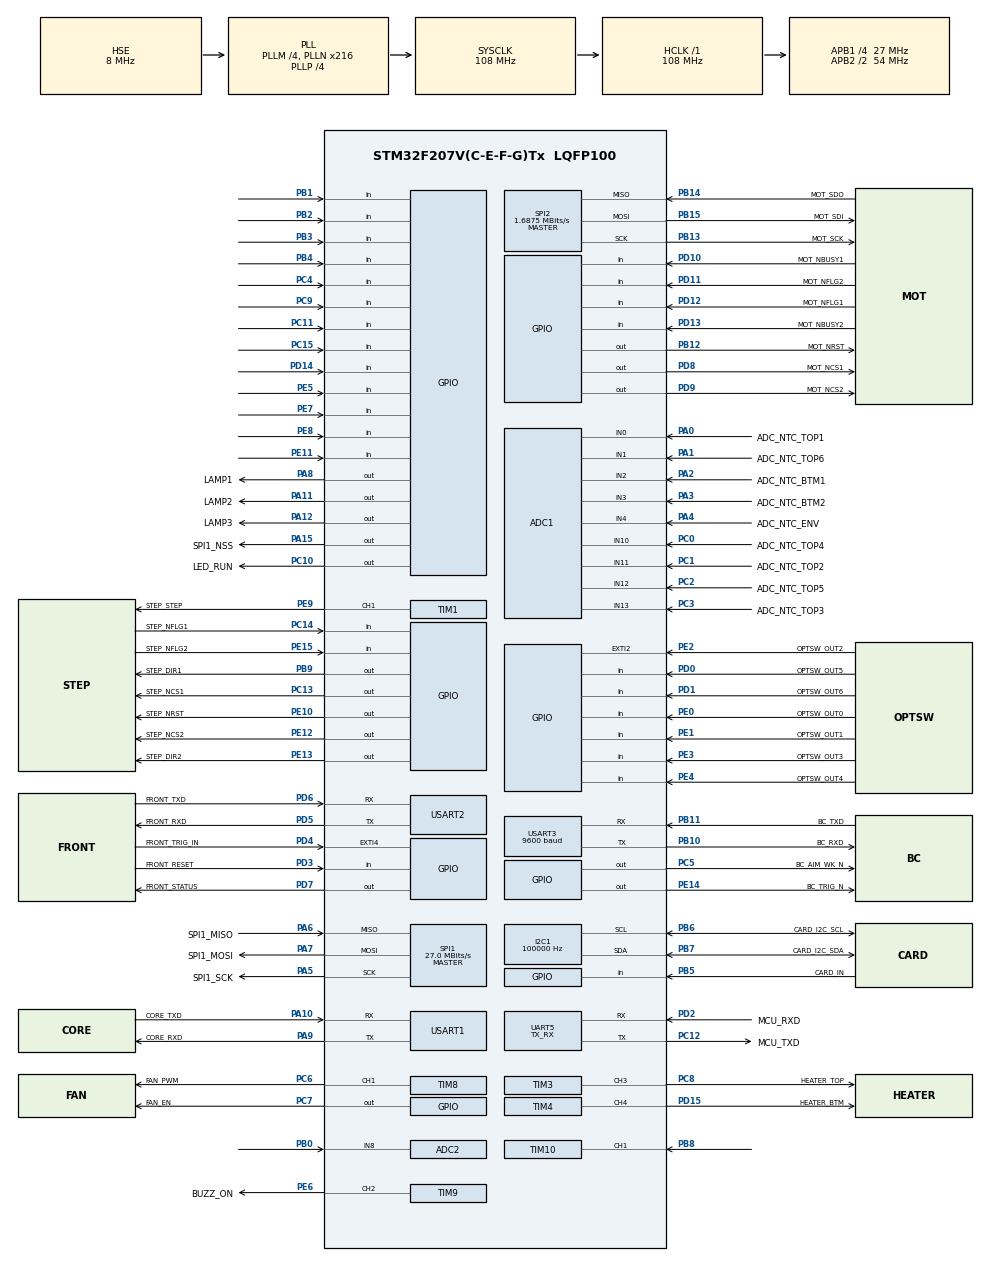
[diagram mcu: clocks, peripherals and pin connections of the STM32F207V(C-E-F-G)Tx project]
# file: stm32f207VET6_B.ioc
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ADC1.Channel-0\#ChannelRegularConversion=ADC_CHANNEL_0
ADC1.Channel-1\#ChannelRegularConversion=ADC_CHANNEL_11
ADC1.Channel-2\#ChannelRegularConversion=ADC_CHANNEL_13
ADC1.Channel-3\#ChannelRegularConversion=ADC_CHANNEL_10
ADC1.Channel-4\#ChannelRegularConversion=ADC_CHANNEL_12
ADC1.Channel-5\#ChannelRegularConversion=ADC_CHANNEL_1
ADC1.Channel-6\#ChannelRegularConversion=ADC_CHANNEL_2
ADC1.Channel-7\#ChannelRegularConversion=ADC_CHANNEL_3
ADC1.Channel-8\#ChannelRegularConversion=ADC_CHANNEL_4
ADC1.ContinuousConvMode=DISABLE
ADC1.DMAContinuousRequests=ENABLE
ADC1.EOCSelection=ADC_EOC_SEQ_CONV
ADC1.ExternalTrigConv=ADC_EXTERNALTRIGCONV_T2_TRGO
ADC1.NbrOfConversion=9
ADC1.NbrOfConversionFlag=1
ADC1.Rank-0\#ChannelRegularConversion=1
ADC1.Rank-1\#ChannelRegularConversion=2
ADC1.Rank-2\#ChannelRegularConversion=3
ADC1.Rank-3\#ChannelRegularConversion=4
ADC1.Rank-4\#ChannelRegularConversion=5
ADC1.Rank-5\#ChannelRegularConversion=6
ADC1.Rank-6\#ChannelRegularConversion=7
ADC1.Rank-7\#ChannelRegularConversion=8
ADC1.Rank-8\#ChannelRegularConversion=9
ADC1.SamplingTime-0\#ChannelRegularConversion=ADC_SAMPLETIME_56CYCLES
ADC1.SamplingTime-1\#ChannelRegularConversion=ADC_SAMPLETIME_56CYCLES
ADC1.SamplingTime-2\#ChannelRegularConversion=ADC_SAMPLETIME_56CYCLES
ADC1.SamplingTime-3\#ChannelRegularConversion=ADC_SAMPLETIME_56CYCLES
ADC1.SamplingTime-4\#ChannelRegularConversion=ADC_SAMPLETIME_56CYCLES
ADC1.SamplingTime-5\#ChannelRegularConversion=ADC_SAMPLETIME_56CYCLES
ADC1.SamplingTime-6\#ChannelRegularConversion=ADC_SAMPLETIME_56CYCLES
ADC1.SamplingTime-7\#ChannelRegularConversion=ADC_SAMPLETIME_56CYCLES
ADC1.SamplingTime-8\#ChannelRegularConversion=ADC_SAMPLETIME_56CYCLES
ADC1.master=1
ADC2.Channel-0\#ChannelRegularConversion=ADC_CHANNEL_8
ADC2.NbrOfConversion=1
ADC2.NbrOfConversionFlag=1
ADC2.Rank-0\#ChannelRegularConversion=1
ADC2.SamplingTime-0\#ChannelRegularConversion=ADC_SAMPLETIME_56CYCLES
Dma.ADC1.6.Direction=DMA_PERIPH_TO_MEMORY
Dma.ADC1.6.FIFOMode=DMA_FIFOMODE_DISABLE
Dma.ADC1.6.Instance=DMA2_Stream0
Dma.ADC1.6.MemDataAlignment=DMA_MDATAALIGN_WORD
Dma.ADC1.6.MemInc=DMA_MINC_ENABLE
Dma.ADC1.6.Mode=DMA_CIRCULAR
Dma.ADC1.6.PeriphDataAlignment=DMA_PDATAALIGN_WORD
Dma.ADC1.6.PeriphInc=DMA_PINC_DISABLE
Dma.ADC1.6.Priority=DMA_PRIORITY_MEDIUM
Dma.Request0=UART5_RX
Dma.Request1=USART1_RX
Dma.Request2=USART1_TX
Dma.Request3=USART2_RX
Dma.Request4=USART2_TX
Dma.Request5=TIM1_UP
Dma.Request6=ADC1
Dma.Request7=UART5_TX
Dma.TIM1_UP.5.Direction=DMA_MEMORY_TO_PERIPH
Dma.TIM1_UP.5.FIFOMode=DMA_FIFOMODE_DISABLE
Dma.TIM1_UP.5.Instance=DMA2_Stream5
Dma.TIM1_UP.5.MemDataAlignment=DMA_MDATAALIGN_WORD
Dma.TIM1_UP.5.MemInc=DMA_MINC_ENABLE
Dma.TIM1_UP.5.Mode=DMA_NORMAL
Dma.TIM1_UP.5.PeriphDataAlignment=DMA_PDATAALIGN_WORD
Dma.TIM1_UP.5.PeriphInc=DMA_PINC_DISABLE
Dma.TIM1_UP.5.Priority=DMA_PRIORITY_HIGH
Dma.UART5_RX.0.Direction=DMA_PERIPH_TO_MEMORY
Dma.UART5_RX.0.FIFOMode=DMA_FIFOMODE_DISABLE
Dma.UART5_RX.0.Instance=DMA1_Stream0
Dma.UART5_RX.0.MemDataAlignment=DMA_MDATAALIGN_BYTE
Dma.UART5_RX.0.MemInc=DMA_MINC_ENABLE
Dma.UART5_RX.0.Mode=DMA_CIRCULAR
Dma.UART5_RX.0.PeriphDataAlignment=DMA_PDATAALIGN_BYTE
Dma.UART5_RX.0.PeriphInc=DMA_PINC_DISABLE
Dma.UART5_RX.0.Priority=DMA_PRIORITY_LOW
Dma.UART5_TX.7.Direction=DMA_MEMORY_TO_PERIPH
Dma.UART5_TX.7.FIFOMode=DMA_FIFOMODE_DISABLE
Dma.UART5_TX.7.Instance=DMA1_Stream7
Dma.UART5_TX.7.MemDataAlignment=DMA_MDATAALIGN_BYTE
Dma.UART5_TX.7.MemInc=DMA_MINC_ENABLE
Dma.UART5_TX.7.Mode=DMA_NORMAL
Dma.UART5_TX.7.PeriphDataAlignment=DMA_PDATAALIGN_BYTE
Dma.UART5_TX.7.PeriphInc=DMA_PINC_DISABLE
Dma.UART5_TX.7.Priority=DMA_PRIORITY_MEDIUM
Dma.USART1_RX.1.Direction=DMA_PERIPH_TO_MEMORY
Dma.USART1_RX.1.FIFOMode=DMA_FIFOMODE_DISABLE
Dma.USART1_RX.1.Instance=DMA2_Stream2
Dma.USART1_RX.1.MemDataAlignment=DMA_MDATAALIGN_BYTE
Dma.USART1_RX.1.MemInc=DMA_MINC_ENABLE
Dma.USART1_RX.1.Mode=DMA_CIRCULAR
Dma.USART1_RX.1.PeriphDataAlignment=DMA_PDATAALIGN_BYTE
Dma.USART1_RX.1.PeriphInc=DMA_PINC_DISABLE
Dma.USART1_RX.1.Priority=DMA_PRIORITY_LOW
Dma.USART1_TX.2.Direction=DMA_MEMORY_TO_PERIPH
Dma.USART1_TX.2.FIFOMode=DMA_FIFOMODE_DISABLE
Dma.USART1_TX.2.Instance=DMA2_Stream7
Dma.USART1_TX.2.MemDataAlignment=DMA_MDATAALIGN_BYTE
Dma.USART1_TX.2.MemInc=DMA_MINC_ENABLE
Dma.USART1_TX.2.Mode=DMA_NORMAL
Dma.USART1_TX.2.PeriphDataAlignment=DMA_PDATAALIGN_BYTE
Dma.USART1_TX.2.PeriphInc=DMA_PINC_DISABLE
Dma.USART1_TX.2.Priority=DMA_PRIORITY_MEDIUM
Dma.USART2_RX.3.Direction=DMA_PERIPH_TO_MEMORY
Dma.USART2_RX.3.FIFOMode=DMA_FIFOMODE_DISABLE
Dma.USART2_RX.3.Instance=DMA1_Stream5
Dma.USART2_RX.3.MemDataAlignment=DMA_MDATAALIGN_BYTE
Dma.USART2_RX.3.MemInc=DMA_MINC_ENABLE
Dma.USART2_RX.3.Mode=DMA_CIRCULAR
Dma.USART2_RX.3.PeriphDataAlignment=DMA_PDATAALIGN_BYTE
Dma.USART2_RX.3.PeriphInc=DMA_PINC_DISABLE
Dma.USART2_RX.3.Priority=DMA_PRIORITY_HIGH
Dma.USART2_TX.4.Direction=DMA_MEMORY_TO_PERIPH
Dma.USART2_TX.4.FIFOMode=DMA_FIFOMODE_DISABLE
Dma.USART2_TX.4.Instance=DMA1_Stream6
Dma.USART2_TX.4.MemDataAlignment=DMA_MDATAALIGN_BYTE
Dma.USART2_TX.4.MemInc=DMA_MINC_ENABLE
Dma.USART2_TX.4.Mode=DMA_NORMAL
Dma.USART2_TX.4.PeriphDataAlignment=DMA_PDATAALIGN_BYTE
Dma.USART2_TX.4.PeriphInc=DMA_PINC_DISABLE
Dma.USART2_TX.4.Priority=DMA_PRIORITY_HIGH
FREERTOS.HEAP_NUMBER=2
FREERTOS.INCLUDE_vTaskDelayUntil=1
FREERTOS.INCLUDE_vTaskDelete=0
FREERTOS.MEMORY_ALLOCATION=0
FREERTOS.Tasks01=defaultTask,0,128,StartDefaultTask,Default,NULL,Dynamic,NULL,NULL
FREERTOS.configGENERATE_RUN_TIME_STATS=0
FREERTOS.configTIMER_TASK_PRIORITY=7
FREERTOS.configTIMER_TASK_STACK_DEPTH=192
FREERTOS.configTOTAL_HEAP_SIZE=20480
FREERTOS.configUSE_STATS_FORMATTING_FUNCTIONS=0
FREERTOS.configUSE_TIMERS=1
I2C1.ClockSpeed=100000
I2C1.I2C_Mode=I2C_Fast
Mcu.Family=STM32F2
Mcu.Name=STM32F207V(C-E-F-G)Tx
Mcu.Package=LQFP100
NVIC.DMA1_Stream0_IRQn=true\:5\:0\:false\:false\:true\:true\:false\:true
NVIC.DMA1_Stream5_IRQn=true\:5\:0\:false\:false\:true\:true\:false\:true
NVIC.DMA1_Stream6_IRQn=true\:5\:0\:false\:false\:true\:true\:false\:true
NVIC.DMA1_Stream7_IRQn=true\:5\:0\:false\:false\:true\:true\:false\:true
NVIC.DMA2_Stream0_IRQn=true\:5\:0\:false\:false\:true\:true\:false\:true
NVIC.DMA2_Stream2_IRQn=true\:5\:0\:false\:false\:true\:true\:false\:true
NVIC.DMA2_Stream5_IRQn=true\:6\:0\:true\:false\:true\:true\:false\:true
NVIC.DMA2_Stream7_IRQn=true\:5\:0\:false\:false\:true\:true\:false\:true
NVIC.EXTI2_IRQn=true\:5\:0\:false\:false\:true\:true\:true\:true
NVIC.EXTI4_IRQn=true\:5\:0\:false\:false\:true\:true\:true\:true
NVIC.PriorityGroup=NVIC_PRIORITYGROUP_4
NVIC.TIM1_UP_TIM10_IRQn=true\:5\:0\:false\:false\:true\:true\:true\:true
NVIC.TIM6_DAC_IRQn=true\:0\:0\:true\:false\:true\:false\:true\:true
NVIC.TIM7_IRQn=true\:0\:0\:false\:false\:true\:false\:true\:true
NVIC.TIM8_TRG_COM_TIM14_IRQn=true\:0\:0\:false\:false\:true\:false\:false\:true
NVIC.TimeBase=TIM8_TRG_COM_TIM14_IRQn
NVIC.TimeBaseIP=TIM14
NVIC.UART5_IRQn=true\:5\:0\:false\:false\:true\:true\:true\:true
NVIC.USART1_IRQn=true\:5\:0\:false\:false\:true\:true\:true\:true
NVIC.USART2_IRQn=true\:5\:0\:false\:false\:true\:true\:true\:true
PA0-WKUP.GPIO_Label=ADC_NTC_TOP1
PA0-WKUP.Signal=ADCx_IN0
PA1.GPIO_Label=ADC_NTC_TOP6
PA1.Signal=ADCx_IN1
PA10.GPIO_Label=CORE_TXD
PA10.Mode=Asynchronous
PA10.Signal=USART1_RX
PA11.GPIO_Label=LAMP2
PA11.Signal=GPIO_Output
PA12.GPIO_Label=LAMP3
PA12.Signal=GPIO_Output
PA13.Mode=Serial_Wire
PA13.Signal=SYS_JTMS-SWDIO
PA14.Mode=Serial_Wire
PA14.Signal=SYS_JTCK-SWCLK
PA15.GPIO_Label=SPI1_NSS
PA15.PinState=GPIO_PIN_SET
PA15.Signal=GPIO_Output
PA2.GPIO_Label=ADC_NTC_BTM1
PA2.Signal=ADCx_IN2
PA3.GPIO_Label=ADC_NTC_BTM2
PA3.Signal=ADCx_IN3
PA4.GPIO_Label=ADC_NTC_ENV
PA4.Signal=ADCx_IN4
PA5.GPIO_Label=SPI1_SCK
PA5.GPIO_Mode=GPIO_MODE_AF_PP
PA5.GPIO_PuPd=GPIO_NOPULL
PA5.Mode=Full_Duplex_Master
PA5.Signal=SPI1_SCK
PA6.GPIO_Label=SPI1_MISO
PA6.GPIO_Mode=GPIO_MODE_AF_PP
PA6.GPIO_PuPd=GPIO_NOPULL
PA6.Mode=Full_Duplex_Master
PA6.Signal=SPI1_MISO
PA7.GPIO_Label=SPI1_MOSI
PA7.GPIO_Mode=GPIO_MODE_AF_PP
PA7.GPIO_PuPd=GPIO_NOPULL
PA7.Mode=Full_Duplex_Master
PA7.Signal=SPI1_MOSI
PA8.GPIO_Label=LAMP1
PA8.Signal=GPIO_Output
PA9.GPIO_Label=CORE_RXD
PA9.Mode=Asynchronous
PA9.Signal=USART1_TX
PB0.Signal=ADCx_IN8
PB1.Signal=GPIO_Input
PB10.GPIO_Label=BC_RXD
PB10.Mode=Asynchronous
PB10.Signal=USART3_TX
PB11.GPIO_Label=BC_TXD
PB11.Mode=Asynchronous
PB11.Signal=USART3_RX
PB12.GPIO_Label=MOT_NRST
PB12.PinState=GPIO_PIN_SET
PB12.Signal=GPIO_Output
PB13.GPIO_Label=MOT_SCK
PB13.GPIO_Speed=GPIO_SPEED_FREQ_LOW
PB13.Mode=Full_Duplex_Master
PB13.Signal=SPI2_SCK
PB14.GPIO_Label=MOT_SDO
PB14.GPIO_Speed=GPIO_SPEED_FREQ_LOW
PB14.Mode=Full_Duplex_Master
PB14.Signal=SPI2_MISO
PB15.GPIO_Label=MOT_SDI
PB15.GPIO_Speed=GPIO_SPEED_FREQ_LOW
PB15.Mode=Full_Duplex_Master
PB15.Signal=SPI2_MOSI
PB2.Signal=GPIO_Input
PB3.Signal=GPIO_Input
PB4.Signal=GPIO_Input
PB5.GPIO_Label=CARD_IN
PB5.Signal=GPIO_Input
PB6.GPIO_Label=CARD_I2C_SCL
PB6.Mode=I2C
PB6.Signal=I2C1_SCL
PB7.GPIO_Label=CARD_I2C_SDA
PB7.Mode=I2C
PB7.Signal=I2C1_SDA
PB8.Signal=S_TIM10_CH1
PB9.GPIO_Label=STEP_DIR1
PB9.Signal=GPIO_Output
PC0.GPIO_Label=ADC_NTC_TOP4
PC0.Signal=ADCx_IN10
PC1.GPIO_Label=ADC_NTC_TOP2
PC1.Signal=ADCx_IN11
PC10.GPIO_Label=LED_RUN
PC10.Signal=GPIO_Output
PC11.Signal=GPIO_Input
PC12.GPIO_Label=MCU_TXD
PC12.Mode=Asynchronous
PC12.Signal=UART5_TX
PC13.GPIO_Label=STEP_NCS1
PC13.Signal=GPIO_Output
PC14-OSC32_IN.GPIO_Label=STEP_NFLG1
PC14-OSC32_IN.Signal=GPIO_Input
PC15-OSC32_OUT.Signal=GPIO_Input
PC2.GPIO_Label=ADC_NTC_TOP5
PC2.Signal=ADCx_IN12
PC3.GPIO_Label=ADC_NTC_TOP3
PC3.Signal=ADCx_IN13
PC4.Signal=GPIO_Input
PC5.GPIO_Label=BC_AIM_WK_N
PC5.PinState=GPIO_PIN_SET
PC5.Signal=GPIO_Output
PC6.GPIO_Label=FAN_PWM
PC6.Signal=S_TIM8_CH1
PC7.GPIO_Label=FAN_EN
PC7.Signal=GPIO_Output
PC8.GPIO_Label=HEATER_TOP
PC8.Signal=S_TIM3_CH3
PC9.Signal=GPIO_Input
PD0.GPIO_Label=OPTSW_OUT5
PD0.Signal=GPIO_Input
PD1.GPIO_Label=OPTSW_OUT6
PD1.Signal=GPIO_Input
PD10.GPIO_Label=MOT_NBUSY1
PD10.Signal=GPIO_Input
PD11.GPIO_Label=MOT_NFLG2
PD11.Signal=GPIO_Input
PD12.GPIO_Label=MOT_NFLG1
PD12.Signal=GPIO_Input
PD13.GPIO_Label=MOT_NBUSY2
PD13.Signal=GPIO_Input
PD14.Signal=GPIO_Input
PD15.GPIO_Label=HEATER_BTM
PD15.Signal=S_TIM4_CH4
PD2.GPIO_Label=MCU_RXD
PD2.Mode=Asynchronous
PD2.Signal=UART5_RX
PD3.GPIO_Label=FRONT_RESET
PD3.Signal=GPIO_Input
PD4.GPIO_Label=FRONT_TRIG_IN
PD4.GPIO_ModeDefaultEXTI=GPIO_MODE_IT_RISING_FALLING
PD4.Signal=GPXTI4
PD5.GPIO_Label=FRONT_RXD
PD5.Mode=Asynchronous
PD5.Signal=USART2_TX
PD6.GPIO_Label=FRONT_TXD
PD6.Mode=Asynchronous
PD6.Signal=USART2_RX
PD7.GPIO_Label=FRONT_STATUS
PD7.GPIO_Speed=GPIO_SPEED_FREQ_VERY_HIGH
PD7.PinState=GPIO_PIN_SET
PD7.Signal=GPIO_Output
PD8.GPIO_Label=MOT_NCS1
PD8.PinState=GPIO_PIN_SET
PD8.Signal=GPIO_Output
PD9.GPIO_Label=MOT_NCS2
PD9.PinState=GPIO_PIN_SET
PD9.Signal=GPIO_Output
PE0.GPIO_Label=OPTSW_OUT0
PE0.GPIO_PuPd=GPIO_PULLUP
PE0.Signal=GPIO_Input
PE1.GPIO_Label=OPTSW_OUT1
PE1.GPIO_PuPd=GPIO_PULLUP
PE1.Signal=GPIO_Input
PE10.GPIO_Label=STEP_NRST
PE10.PinState=GPIO_PIN_SET
PE10.Signal=GPIO_Output
PE11.Signal=GPIO_Input
PE12.GPIO_Label=STEP_NCS2
PE12.Signal=GPIO_Output
PE13.GPIO_Label=STEP_DIR2
PE13.Signal=GPIO_Output
PE14.GPIO_Label=BC_TRIG_N
PE14.PinState=GPIO_PIN_SET
PE14.Signal=GPIO_Output
PE15.GPIO_Label=STEP_NFLG2
PE15.Signal=GPIO_Input
PE2.GPIO_Label=OPTSW_OUT2
PE2.GPIO_ModeDefaultEXTI=GPIO_MODE_IT_RISING_FALLING
PE2.Signal=GPXTI2
PE3.GPIO_Label=OPTSW_OUT3
PE3.GPIO_PuPd=GPIO_PULLUP
PE3.Signal=GPIO_Input
PE4.GPIO_Label=OPTSW_OUT4
PE4.GPIO_PuPd=GPIO_PULLUP
PE4.Signal=GPIO_Input
PE5.Signal=GPIO_Input
PE6.GPIO_Label=BUZZ_ON
PE6.Signal=S_TIM9_CH2
PE7.Signal=GPIO_Input
PE8.Signal=GPIO_Input
PE9.GPIO_Label=STEP_STEP
PE9.Signal=S_TIM1_CH1
PH0-OSC_IN.Mode=HSE-External-Oscillator
PH0-OSC_IN.Signal=RCC_OSC_IN
PH1-OSC_OUT.Mode=HSE-External-Oscillator
PH1-OSC_OUT.Signal=RCC_OSC_OUT
ProjectManager.HeapSize=0x200
ProjectManager.StackSize=0x400
ProjectManager.TargetToolchain=STM32CubeIDE
RCC.48MHZClocksFreq_Value=108000000
RCC.AHBFreq_Value=108000000
RCC.APB1CLKDivider=RCC_HCLK_DIV4
RCC.APB1Freq_Value=27000000
RCC.APB1TimFreq_Value=54000000
RCC.APB2CLKDivider=RCC_HCLK_DIV2
RCC.APB2Freq_Value=54000000
RCC.APB2TimFreq_Value=108000000
RCC.CortexFreq_Value=108000000
RCC.EnbaleCSS=true
RCC.HCLKFreq_Value=108000000
RCC.HSE_VALUE=8000000
RCC.HSI_VALUE=16000000
RCC.LSE_VALUE=32768
RCC.PLLM=4
RCC.PLLN=216
RCC.PLLP=RCC_PLLP_DIV4
RCC.PLLSourceVirtual=RCC_PLLSOURCE_HSE
RCC.SYSCLKFreq_VALUE=108000000
RCC.SYSCLKSource=RCC_SYSCLKSOURCE_PLLCLK
RCC.VCOOutputFreq_Value=432000000
SH.ADCx_IN0.0=ADC1_IN0,IN0
SH.ADCx_IN1.0=ADC1_IN1,IN1
SH.ADCx_IN10.0=ADC1_IN10,IN10
SH.ADCx_IN11.0=ADC1_IN11,IN11
SH.ADCx_IN12.0=ADC1_IN12,IN12
SH.ADCx_IN13.0=ADC1_IN13,IN13
SH.ADCx_IN2.0=ADC1_IN2,IN2
SH.ADCx_IN3.0=ADC1_IN3,IN3
SH.ADCx_IN4.0=ADC1_IN4,IN4
SH.ADCx_IN8.0=ADC2_IN8,IN8
SH.S_TIM10_CH1.0=TIM10_CH1,Input_Capture1_from_TI1
SH.S_TIM1_CH1.0=TIM1_CH1,PWM Generation1 CH1
SH.S_TIM3_CH3.0=TIM3_CH3,PWM Generation3 CH3
SH.S_TIM4_CH4.0=TIM4_CH4,PWM Generation4 CH4
SH.S_TIM8_CH1.0=TIM8_CH1,PWM Generation1 CH1
SH.S_TIM9_CH2.0=TIM9_CH2,PWM Generation2 CH2
SPI1.BaudRatePrescaler=SPI_BAUDRATEPRESCALER_2
SPI1.CLKPhase=SPI_PHASE_2EDGE
SPI1.CLKPolarity=SPI_POLARITY_HIGH
SPI1.CalculateBaudRate=27.0 MBits/s
SPI1.Direction=SPI_DIRECTION_2LINES
SPI1.Mode=SPI_MODE_MASTER
SPI1.VirtualType=VM_MASTER
SPI2.BaudRatePrescaler=SPI_BAUDRATEPRESCALER_16
SPI2.CLKPhase=SPI_PHASE_2EDGE
SPI2.CLKPolarity=SPI_POLARITY_HIGH
SPI2.CRCCalculation=SPI_CRCCALCULATION_DISABLE
SPI2.CalculateBaudRate=1.6875 MBits/s
SPI2.DataSize=SPI_DATASIZE_8BIT
SPI2.Direction=SPI_DIRECTION_2LINES
SPI2.Mode=SPI_MODE_MASTER
SPI2.VirtualType=VM_MASTER
TIM1.Channel-PWM\ Generation1\ CH1=TIM_CHANNEL_1
TIM1.Period=STEP_TIM_ARR
TIM1.Prescaler=STEP_TIM_PSC
TIM1.Pulse-PWM\ Generation1\ CH1=STEP_TIM_PUL
TIM1.RepetitionCounter=STEP_TIM_RCR
TIM10.AutoReloadPreload=TIM_AUTORELOAD_PRELOAD_DISABLE
TIM10.Channel=TIM_CHANNEL_1
TIM10.ICFilter_CH1=FAN_IC_IF
TIM10.ICPolarity_CH1=TIM_INPUTCHANNELPOLARITY_RISING
TIM10.Period=FAN_IC_ARR
TIM10.Prescaler=FAN_IC_PSC
TIM2.AutoReloadPreload=TIM_AUTORELOAD_PRELOAD_ENABLE
TIM2.Period=TEMP_ARR
TIM2.Prescaler=TEMP_PSC
TIM2.TIM_MasterOutputTrigger=TIM_TRGO_UPDATE
TIM3.Channel-PWM\ Generation3\ CH3=TIM_CHANNEL_3
TIM3.Period=HEATER_TOP_ARR
TIM3.Prescaler=HEATER_TOP_PSC
TIM3.Pulse-PWM\ Generation3\ CH3=HEATER_TOP_CCR
TIM4.Channel-PWM\ Generation4\ CH4=TIM_CHANNEL_4
TIM4.Period=HEATER_BTM_ARR
TIM4.Prescaler=HEATER_BTM_PSC
TIM4.Pulse-PWM\ Generation4\ CH4=HEATER_BTM_CCR
TIM6.Period=COMM_DATA_WH_TIMER_PERIOD
TIM6.Prescaler=COMM_DATA_WH_TIMER_PRESCALER
TIM7.Period=COMM_DATA_PD_TIMER_PERIOD
TIM7.Prescaler=COMM_DATA_PD_TIMER_PRESCALER
TIM8.AutoReloadPreload=TIM_AUTORELOAD_PRELOAD_DISABLE
TIM8.Channel-PWM\ Generation1\ CH1=TIM_CHANNEL_1
TIM8.Period=FAN_ARR
TIM8.Prescaler=FAN_PSC
TIM8.Pulse-PWM\ Generation1\ CH1=FAN_CCR
TIM8.RepetitionCounter=0
TIM8.TIM_MasterOutputTrigger=TIM_TRGO_RESET
TIM9.Channel-PWM\ Generation2\ CH2=TIM_CHANNEL_2
TIM9.Period=36
TIM9.Prescaler=BEEP_TIM_PSC
TIM9.Pulse-PWM\ Generation2\ CH2=18
UART5.Mode=MODE_TX_RX
UART5.VirtualMode=Asynchronous
USART1.VirtualMode=VM_ASYNC
USART2.VirtualMode=VM_ASYNC
USART3.BaudRate=9600
USART3.VirtualMode=VM_ASYNC
VP_FREERTOS_VS_CMSIS_V2.Mode=CMSIS_V2
VP_SYS_VS_tim14.Mode=TIM14
VP_TIM10_VS_ClockSourceINT.Mode=Enable_Timer
VP_TIM1_VS_ClockSourceINT.Mode=Internal
VP_TIM2_VS_ClockSourceINT.Mode=Internal
VP_TIM4_VS_ClockSourceINT.Mode=Internal
VP_TIM6_VS_ClockSourceINT.Mode=Enable_Timer
VP_TIM7_VS_ClockSourceINT.Mode=Enable_Timer
VP_TIM8_VS_ClockSourceINT.Mode=Internal
VP_TIM9_VS_ClockSourceINT.Mode=Internal
board=custom

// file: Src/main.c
/* USER CODE BEGIN Header */
/**
 ******************************************************************************
 * @file           : main.c
 * @brief          : Main program body
 ******************************************************************************
 * @attention
 *
 * <h2><center>&copy; Copyright (c) 2019 STMicroelectronics.
 * All rights reserved.</center></h2>
 *
 * This software component is licensed by ST under BSD 3-Clause license,
 * the "License"; You may not use this file except in compliance with the
 * License. You may obtain a copy of the License at:
 *                        opensource.org/licenses/BSD-3-Clause
 *
 ******************************************************************************
 */
/* USER CODE END Header */

#include "main.h"
#include "cmsis_os.h"

/* USER CODE BEGIN Includes */
#include <stdio.h>
#include <string.h>
#include "comm_out.h"
#include "comm_data.h"
#include "comm_main.h"
#include "m_drv8824.h"
#include "temperature.h"
#include "heater.h"
#include "motor.h"
#include "soft_timer.h"
#include "storge_task.h"
#include "barcode_scan.h"
#include "fan.h"
#include "beep.h"
#include "led.h"
#include "white_motor.h"

/* USER CODE END Includes */

ADC_HandleTypeDef hadc1;
ADC_HandleTypeDef hadc2;
DMA_HandleTypeDef hdma_adc1;

I2C_HandleTypeDef hi2c1;

SPI_HandleTypeDef hspi1;
SPI_HandleTypeDef hspi2;

TIM_HandleTypeDef htim1;
TIM_HandleTypeDef htim2;
TIM_HandleTypeDef htim3;
TIM_HandleTypeDef htim4;
TIM_HandleTypeDef htim6;
TIM_HandleTypeDef htim7;
TIM_HandleTypeDef htim8;
TIM_HandleTypeDef htim9;
TIM_HandleTypeDef htim10;
DMA_HandleTypeDef hdma_tim1_up;

UART_HandleTypeDef huart5;
UART_HandleTypeDef huart1;
UART_HandleTypeDef huart2;
UART_HandleTypeDef huart3;
DMA_HandleTypeDef hdma_uart5_rx;
DMA_HandleTypeDef hdma_uart5_tx;
DMA_HandleTypeDef hdma_usart1_rx;
DMA_HandleTypeDef hdma_usart1_tx;
DMA_HandleTypeDef hdma_usart2_rx;
DMA_HandleTypeDef hdma_usart2_tx;

/* Definitions for defaultTask */
osThreadId_t defaultTaskHandle;
const osThreadAttr_t defaultTask_attributes = {.name = "defaultTask", .priority = (osPriority_t)osPriorityNormal, .stack_size = 128};

void SystemClock_Config(void);
static void MX_GPIO_Init(void);
static void MX_DMA_Init(void);
static void MX_UART5_Init(void);
static void MX_USART3_UART_Init(void);
static void MX_SPI2_Init(void);
static void MX_USART1_UART_Init(void);
static void MX_USART2_UART_Init(void);
static void MX_TIM1_Init(void);
static void MX_TIM9_Init(void);
static void MX_ADC1_Init(void);
static void MX_TIM8_Init(void);
static void MX_TIM3_Init(void);
static void MX_TIM4_Init(void);
static void MX_I2C1_Init(void);
static void MX_SPI1_Init(void);
static void MX_TIM6_Init(void);
static void MX_TIM2_Init(void);
static void MX_TIM10_Init(void);
static void MX_TIM7_Init(void);
static void MX_ADC2_Init(void);
void StartDefaultTask(void * argument);

/* USER CODE BEGIN PFP */
static void Miscellaneous_Task(void * argument);
static TaskHandle_t Miscellaneous_Task_Handle = NULL;
static uint8_t Miscellaneous_Task_State = 0;

/* USER CODE END PFP */

int main(void)
{

    /* MCU Configuration--------------------------------------------------------*/

    /* Reset of all peripherals, Initializes the Flash interface and the Systick. */
    HAL_Init();

    /* Configure the system clock */
    SystemClock_Config();

    /* Initialize all configured peripherals */
    MX_GPIO_Init();
    MX_DMA_Init();
    MX_UART5_Init();
    MX_USART3_UART_Init();
    MX_SPI2_Init();
    MX_USART1_UART_Init();
    MX_USART2_UART_Init();
    MX_TIM1_Init();
    MX_TIM9_Init();
    MX_ADC1_Init();
    MX_TIM8_Init();
    MX_TIM3_Init();
    MX_TIM4_Init();
    MX_I2C1_Init();
    MX_SPI1_Init();
    MX_TIM6_Init();
    MX_TIM2_Init();
    MX_TIM10_Init();
    MX_TIM7_Init();
    MX_ADC2_Init();
    /* USER CODE BEGIN 2 */

    /* soft timer task */
    soft_timer_Init();

    /* communication task */
    SerialInit();
    comm_Data_Init();
    comm_Out_Init();
    comm_Main_Init();
    /* motor task */
    motor_Init();
    /* storge task */
    storgeTaskInit();

    if (xTaskCreate(Miscellaneous_Task, "TASK_MISC", 160, NULL, 1, &Miscellaneous_Task_Handle) != pdPASS) {
        FL_Error_Handler(__FILE__, __LINE__);
    }

    /* Start the scheduler. */
    vTaskStartScheduler();
#if 0
  /* USER CODE END 2 */

  /* Init scheduler */
  osKernelInitialize();

  /* Create the thread(s) */
  /* creation of defaultTask */
  defaultTaskHandle = osThreadNew(StartDefaultTask, NULL, &defaultTask_attributes);

  /* Start scheduler */
  osKernelStart();

  /* We should never get here as control is now taken by the scheduler */
  /* Infinite loop */
    while (1) {

    /* USER CODE BEGIN 3 */
    }
#endif
    /* USER CODE END 3 */
}

void SystemClock_Config(void)
{
    RCC_OscInitTypeDef RCC_OscInitStruct = {0};
    RCC_ClkInitTypeDef RCC_ClkInitStruct = {0};

    /** Initializes the CPU, AHB and APB busses clocks
     */
    RCC_OscInitStruct.OscillatorType = RCC_OSCILLATORTYPE_HSE;
    RCC_OscInitStruct.HSEState = RCC_HSE_ON;
    RCC_OscInitStruct.PLL.PLLState = RCC_PLL_ON;
    RCC_OscInitStruct.PLL.PLLSource = RCC_PLLSOURCE_HSE;
    RCC_OscInitStruct.PLL.PLLM = 4;
    RCC_OscInitStruct.PLL.PLLN = 216;
    RCC_OscInitStruct.PLL.PLLP = RCC_PLLP_DIV4;
    RCC_OscInitStruct.PLL.PLLQ = 4;
    if (HAL_RCC_OscConfig(&RCC_OscInitStruct) != HAL_OK) {
        Error_Handler();
    }
    /** Initializes the CPU, AHB and APB busses clocks
     */
    RCC_ClkInitStruct.ClockType = RCC_CLOCKTYPE_HCLK | RCC_CLOCKTYPE_SYSCLK | RCC_CLOCKTYPE_PCLK1 | RCC_CLOCKTYPE_PCLK2;
    RCC_ClkInitStruct.SYSCLKSource = RCC_SYSCLKSOURCE_PLLCLK;
    RCC_ClkInitStruct.AHBCLKDivider = RCC_SYSCLK_DIV1;
    RCC_ClkInitStruct.APB1CLKDivider = RCC_HCLK_DIV4;
    RCC_ClkInitStruct.APB2CLKDivider = RCC_HCLK_DIV2;

    if (HAL_RCC_ClockConfig(&RCC_ClkInitStruct, FLASH_LATENCY_3) != HAL_OK) {
        Error_Handler();
    }
    /** Enables the Clock Security System
     */
    HAL_RCC_EnableCSS();
}

static void MX_ADC1_Init(void)
{

    ADC_ChannelConfTypeDef sConfig = {0};

    /** Configure the global features of the ADC (Clock, Resolution, Data Alignment and number of conversion)
     */
    hadc1.Instance = ADC1;
    hadc1.Init.ClockPrescaler = ADC_CLOCK_SYNC_PCLK_DIV2;
    hadc1.Init.Resolution = ADC_RESOLUTION_12B;
    hadc1.Init.ScanConvMode = ENABLE;
    hadc1.Init.ContinuousConvMode = DISABLE;
    hadc1.Init.DiscontinuousConvMode = DISABLE;
    hadc1.Init.ExternalTrigConvEdge = ADC_EXTERNALTRIGCONVEDGE_RISING;
    hadc1.Init.ExternalTrigConv = ADC_EXTERNALTRIGCONV_T2_TRGO;
    hadc1.Init.DataAlign = ADC_DATAALIGN_RIGHT;
    hadc1.Init.NbrOfConversion = 9;
    hadc1.Init.DMAContinuousRequests = ENABLE;
    hadc1.Init.EOCSelection = ADC_EOC_SEQ_CONV;
    if (HAL_ADC_Init(&hadc1) != HAL_OK) {
        Error_Handler();
    }
    /** Configure for the selected ADC regular channel its corresponding rank in the sequencer and its sample time.
     */
    sConfig.Channel = ADC_CHANNEL_0;
    sConfig.Rank = 1;
    sConfig.SamplingTime = ADC_SAMPLETIME_56CYCLES;
    if (HAL_ADC_ConfigChannel(&hadc1, &sConfig) != HAL_OK) {
        Error_Handler();
    }
    /** Configure for the selected ADC regular channel its corresponding rank in the sequencer and its sample time.
     */
    sConfig.Channel = ADC_CHANNEL_11;
    sConfig.Rank = 2;
    if (HAL_ADC_ConfigChannel(&hadc1, &sConfig) != HAL_OK) {
        Error_Handler();
    }
    /** Configure for the selected ADC regular channel its corresponding rank in the sequencer and its sample time.
     */
    sConfig.Channel = ADC_CHANNEL_13;
    sConfig.Rank = 3;
    if (HAL_ADC_ConfigChannel(&hadc1, &sConfig) != HAL_OK) {
        Error_Handler();
    }
    /** Configure for the selected ADC regular channel its corresponding rank in the sequencer and its sample time.
     */
    sConfig.Channel = ADC_CHANNEL_10;
    sConfig.Rank = 4;
    if (HAL_ADC_ConfigChannel(&hadc1, &sConfig) != HAL_OK) {
        Error_Handler();
    }
    /** Configure for the selected ADC regular channel its corresponding rank in the sequencer and its sample time.
     */
    sConfig.Channel = ADC_CHANNEL_12;
    sConfig.Rank = 5;
    if (HAL_ADC_ConfigChannel(&hadc1, &sConfig) != HAL_OK) {
        Error_Handler();
    }
    /** Configure for the selected ADC regular channel its corresponding rank in the sequencer and its sample time.
     */
    sConfig.Channel = ADC_CHANNEL_1;
    sConfig.Rank = 6;
    if (HAL_ADC_ConfigChannel(&hadc1, &sConfig) != HAL_OK) {
        Error_Handler();
    }
    /** Configure for the selected ADC regular channel its corresponding rank in the sequencer and its sample time.
     */
    sConfig.Channel = ADC_CHANNEL_2;
    sConfig.Rank = 7;
    if (HAL_ADC_ConfigChannel(&hadc1, &sConfig) != HAL_OK) {
        Error_Handler();
    }
    /** Configure for the selected ADC regular channel its corresponding rank in the sequencer and its sample time.
     */
    sConfig.Channel = ADC_CHANNEL_3;
    sConfig.Rank = 8;
    if (HAL_ADC_ConfigChannel(&hadc1, &sConfig) != HAL_OK) {
        Error_Handler();
    }
    /** Configure for the selected ADC regular channel its corresponding rank in the sequencer and its sample time.
     */
    sConfig.Channel = ADC_CHANNEL_4;
    sConfig.Rank = 9;
    if (HAL_ADC_ConfigChannel(&hadc1, &sConfig) != HAL_OK) {
        Error_Handler();
    }
}

static void MX_ADC2_Init(void)
{

    ADC_ChannelConfTypeDef sConfig = {0};

    /** Configure the global features of the ADC (Clock, Resolution, Data Alignment and number of conversion)
     */
    hadc2.Instance = ADC2;
    hadc2.Init.ClockPrescaler = ADC_CLOCK_SYNC_PCLK_DIV2;
    hadc2.Init.Resolution = ADC_RESOLUTION_12B;
    hadc2.Init.ScanConvMode = DISABLE;
    hadc2.Init.ContinuousConvMode = DISABLE;
    hadc2.Init.DiscontinuousConvMode = DISABLE;
    hadc2.Init.ExternalTrigConvEdge = ADC_EXTERNALTRIGCONVEDGE_NONE;
    hadc2.Init.ExternalTrigConv = ADC_SOFTWARE_START;
    hadc2.Init.DataAlign = ADC_DATAALIGN_RIGHT;
    hadc2.Init.NbrOfConversion = 1;
    hadc2.Init.DMAContinuousRequests = DISABLE;
    hadc2.Init.EOCSelection = ADC_EOC_SINGLE_CONV;
    if (HAL_ADC_Init(&hadc2) != HAL_OK) {
        Error_Handler();
    }
    /** Configure for the selected ADC regular channel its corresponding rank in the sequencer and its sample time.
     */
    sConfig.Channel = ADC_CHANNEL_8;
    sConfig.Rank = 1;
    sConfig.SamplingTime = ADC_SAMPLETIME_56CYCLES;
    if (HAL_ADC_ConfigChannel(&hadc2, &sConfig) != HAL_OK) {
        Error_Handler();
    }
}

static void MX_I2C1_Init(void)
{

    hi2c1.Instance = I2C1;
    hi2c1.Init.ClockSpeed = 100000;
    hi2c1.Init.DutyCycle = I2C_DUTYCYCLE_2;
    hi2c1.Init.OwnAddress1 = 0;
    hi2c1.Init.AddressingMode = I2C_ADDRESSINGMODE_7BIT;
    hi2c1.Init.DualAddressMode = I2C_DUALADDRESS_DISABLE;
    hi2c1.Init.OwnAddress2 = 0;
    hi2c1.Init.GeneralCallMode = I2C_GENERALCALL_DISABLE;
    hi2c1.Init.NoStretchMode = I2C_NOSTRETCH_DISABLE;
    if (HAL_I2C_Init(&hi2c1) != HAL_OK) {
        Error_Handler();
    }
}

static void MX_SPI1_Init(void)
{

    /* SPI1 parameter configuration*/
    hspi1.Instance = SPI1;
    hspi1.Init.Mode = SPI_MODE_MASTER;
    hspi1.Init.Direction = SPI_DIRECTION_2LINES;
    hspi1.Init.DataSize = SPI_DATASIZE_8BIT;
    hspi1.Init.CLKPolarity = SPI_POLARITY_HIGH;
    hspi1.Init.CLKPhase = SPI_PHASE_2EDGE;
    hspi1.Init.NSS = SPI_NSS_SOFT;
    hspi1.Init.BaudRatePrescaler = SPI_BAUDRATEPRESCALER_2;
    hspi1.Init.FirstBit = SPI_FIRSTBIT_MSB;
    hspi1.Init.TIMode = SPI_TIMODE_DISABLE;
    hspi1.Init.CRCCalculation = SPI_CRCCALCULATION_DISABLE;
    hspi1.Init.CRCPolynomial = 10;
    if (HAL_SPI_Init(&hspi1) != HAL_OK) {
        Error_Handler();
    }
}

static void MX_SPI2_Init(void)
{

    /* SPI2 parameter configuration*/
    hspi2.Instance = SPI2;
    hspi2.Init.Mode = SPI_MODE_MASTER;
    hspi2.Init.Direction = SPI_DIRECTION_2LINES;
    hspi2.Init.DataSize = SPI_DATASIZE_8BIT;
    hspi2.Init.CLKPolarity = SPI_POLARITY_HIGH;
    hspi2.Init.CLKPhase = SPI_PHASE_2EDGE;
    hspi2.Init.NSS = SPI_NSS_SOFT;
    hspi2.Init.BaudRatePrescaler = SPI_BAUDRATEPRESCALER_16;
    hspi2.Init.FirstBit = SPI_FIRSTBIT_MSB;
    hspi2.Init.TIMode = SPI_TIMODE_DISABLE;
    hspi2.Init.CRCCalculation = SPI_CRCCALCULATION_DISABLE;
    hspi2.Init.CRCPolynomial = 10;
    if (HAL_SPI_Init(&hspi2) != HAL_OK) {
        Error_Handler();
    }
}

static void MX_TIM1_Init(void)
{

    TIM_ClockConfigTypeDef sClockSourceConfig = {0};
    TIM_MasterConfigTypeDef sMasterConfig = {0};
    TIM_OC_InitTypeDef sConfigOC = {0};
    TIM_BreakDeadTimeConfigTypeDef sBreakDeadTimeConfig = {0};

    htim1.Instance = TIM1;
    htim1.Init.Prescaler = STEP_TIM_PSC;
    htim1.Init.CounterMode = TIM_COUNTERMODE_UP;
    htim1.Init.Period = STEP_TIM_ARR;
    htim1.Init.ClockDivision = TIM_CLOCKDIVISION_DIV1;
    htim1.Init.RepetitionCounter = STEP_TIM_RCR;
    htim1.Init.AutoReloadPreload = TIM_AUTORELOAD_PRELOAD_DISABLE;
    if (HAL_TIM_Base_Init(&htim1) != HAL_OK) {
        Error_Handler();
    }
    sClockSourceConfig.ClockSource = TIM_CLOCKSOURCE_INTERNAL;
    if (HAL_TIM_ConfigClockSource(&htim1, &sClockSourceConfig) != HAL_OK) {
        Error_Handler();
    }
    if (HAL_TIM_PWM_Init(&htim1) != HAL_OK) {
        Error_Handler();
    }
    sMasterConfig.MasterOutputTrigger = TIM_TRGO_RESET;
    sMasterConfig.MasterSlaveMode = TIM_MASTERSLAVEMODE_DISABLE;
    if (HAL_TIMEx_MasterConfigSynchronization(&htim1, &sMasterConfig) != HAL_OK) {
        Error_Handler();
    }
    sConfigOC.OCMode = TIM_OCMODE_PWM1;
    sConfigOC.Pulse = STEP_TIM_PUL;
    sConfigOC.OCPolarity = TIM_OCPOLARITY_HIGH;
    sConfigOC.OCNPolarity = TIM_OCNPOLARITY_HIGH;
    sConfigOC.OCFastMode = TIM_OCFAST_DISABLE;
    sConfigOC.OCIdleState = TIM_OCIDLESTATE_RESET;
    sConfigOC.OCNIdleState = TIM_OCNIDLESTATE_RESET;
    if (HAL_TIM_PWM_ConfigChannel(&htim1, &sConfigOC, TIM_CHANNEL_1) != HAL_OK) {
        Error_Handler();
    }
    sBreakDeadTimeConfig.OffStateRunMode = TIM_OSSR_DISABLE;
    sBreakDeadTimeConfig.OffStateIDLEMode = TIM_OSSI_DISABLE;
    sBreakDeadTimeConfig.LockLevel = TIM_LOCKLEVEL_OFF;
    sBreakDeadTimeConfig.DeadTime = 0;
    sBreakDeadTimeConfig.BreakState = TIM_BREAK_DISABLE;
    sBreakDeadTimeConfig.BreakPolarity = TIM_BREAKPOLARITY_HIGH;
    sBreakDeadTimeConfig.AutomaticOutput = TIM_AUTOMATICOUTPUT_DISABLE;
    if (HAL_TIMEx_ConfigBreakDeadTime(&htim1, &sBreakDeadTimeConfig) != HAL_OK) {
        Error_Handler();
    }
    HAL_TIM_MspPostInit(&htim1);
}

static void MX_TIM2_Init(void)
{

    TIM_ClockConfigTypeDef sClockSourceConfig = {0};
    TIM_MasterConfigTypeDef sMasterConfig = {0};

    htim2.Instance = TIM2;
    htim2.Init.Prescaler = TEMP_PSC;
    htim2.Init.CounterMode = TIM_COUNTERMODE_UP;
    htim2.Init.Period = TEMP_ARR;
    htim2.Init.ClockDivision = TIM_CLOCKDIVISION_DIV1;
    htim2.Init.AutoReloadPreload = TIM_AUTORELOAD_PRELOAD_ENABLE;
    if (HAL_TIM_Base_Init(&htim2) != HAL_OK) {
        Error_Handler();
    }
    sClockSourceConfig.ClockSource = TIM_CLOCKSOURCE_INTERNAL;
    if (HAL_TIM_ConfigClockSource(&htim2, &sClockSourceConfig) != HAL_OK) {
        Error_Handler();
    }
    sMasterConfig.MasterOutputTrigger = TIM_TRGO_UPDATE;
    sMasterConfig.MasterSlaveMode = TIM_MASTERSLAVEMODE_DISABLE;
    if (HAL_TIMEx_MasterConfigSynchronization(&htim2, &sMasterConfig) != HAL_OK) {
        Error_Handler();
    }
}

static void MX_TIM3_Init(void)
{

    TIM_MasterConfigTypeDef sMasterConfig = {0};
    TIM_OC_InitTypeDef sConfigOC = {0};

    htim3.Instance = TIM3;
    htim3.Init.Prescaler = HEATER_TOP_PSC;
    htim3.Init.CounterMode = TIM_COUNTERMODE_UP;
    htim3.Init.Period = HEATER_TOP_ARR;
    htim3.Init.ClockDivision = TIM_CLOCKDIVISION_DIV1;
    htim3.Init.AutoReloadPreload = TIM_AUTORELOAD_PRELOAD_DISABLE;
    if (HAL_TIM_PWM_Init(&htim3) != HAL_OK) {
        Error_Handler();
    }
    sMasterConfig.MasterOutputTrigger = TIM_TRGO_RESET;
    sMasterConfig.MasterSlaveMode = TIM_MASTERSLAVEMODE_DISABLE;
    if (HAL_TIMEx_MasterConfigSynchronization(&htim3, &sMasterConfig) != HAL_OK) {
        Error_Handler();
    }
    sConfigOC.OCMode = TIM_OCMODE_PWM1;
    sConfigOC.Pulse = HEATER_TOP_CCR;
    sConfigOC.OCPolarity = TIM_OCPOLARITY_HIGH;
    sConfigOC.OCFastMode = TIM_OCFAST_DISABLE;
    if (HAL_TIM_PWM_ConfigChannel(&htim3, &sConfigOC, TIM_CHANNEL_3) != HAL_OK) {
        Error_Handler();
    }
    HAL_TIM_MspPostInit(&htim3);
}

static void MX_TIM4_Init(void)
{

    TIM_ClockConfigTypeDef sClockSourceConfig = {0};
    TIM_MasterConfigTypeDef sMasterConfig = {0};
    TIM_OC_InitTypeDef sConfigOC = {0};

    htim4.Instance = TIM4;
    htim4.Init.Prescaler = HEATER_BTM_PSC;
    htim4.Init.CounterMode = TIM_COUNTERMODE_UP;
    htim4.Init.Period = HEATER_BTM_ARR;
    htim4.Init.ClockDivision = TIM_CLOCKDIVISION_DIV1;
    htim4.Init.AutoReloadPreload = TIM_AUTORELOAD_PRELOAD_DISABLE;
    if (HAL_TIM_Base_Init(&htim4) != HAL_OK) {
        Error_Handler();
    }
    sClockSourceConfig.ClockSource = TIM_CLOCKSOURCE_INTERNAL;
    if (HAL_TIM_ConfigClockSource(&htim4, &sClockSourceConfig) != HAL_OK) {
        Error_Handler();
    }
    if (HAL_TIM_PWM_Init(&htim4) != HAL_OK) {
        Error_Handler();
    }
    sMasterConfig.MasterOutputTrigger = TIM_TRGO_RESET;
    sMasterConfig.MasterSlaveMode = TIM_MASTERSLAVEMODE_DISABLE;
    if (HAL_TIMEx_MasterConfigSynchronization(&htim4, &sMasterConfig) != HAL_OK) {
        Error_Handler();
    }
    sConfigOC.OCMode = TIM_OCMODE_PWM1;
    sConfigOC.Pulse = HEATER_BTM_CCR;
    sConfigOC.OCPolarity = TIM_OCPOLARITY_HIGH;
    sConfigOC.OCFastMode = TIM_OCFAST_DISABLE;
    if (HAL_TIM_PWM_ConfigChannel(&htim4, &sConfigOC, TIM_CHANNEL_4) != HAL_OK) {
        Error_Handler();
    }
    HAL_TIM_MspPostInit(&htim4);
}

static void MX_TIM6_Init(void)
{

    TIM_MasterConfigTypeDef sMasterConfig = {0};

    htim6.Instance = TIM6;
    htim6.Init.Prescaler = COMM_DATA_WH_TIMER_PRESCALER;
    htim6.Init.CounterMode = TIM_COUNTERMODE_UP;
    htim6.Init.Period = COMM_DATA_WH_TIMER_PERIOD;
    htim6.Init.AutoReloadPreload = TIM_AUTORELOAD_PRELOAD_DISABLE;
    if (HAL_TIM_Base_Init(&htim6) != HAL_OK) {
        Error_Handler();
    }
    sMasterConfig.MasterOutputTrigger = TIM_TRGO_RESET;
    sMasterConfig.MasterSlaveMode = TIM_MASTERSLAVEMODE_DISABLE;
    if (HAL_TIMEx_MasterConfigSynchronization(&htim6, &sMasterConfig) != HAL_OK) {
        Error_Handler();
    }
}

static void MX_TIM7_Init(void)
{

    TIM_MasterConfigTypeDef sMasterConfig = {0};

    htim7.Instance = TIM7;
    htim7.Init.Prescaler = COMM_DATA_PD_TIMER_PRESCALER;
    htim7.Init.CounterMode = TIM_COUNTERMODE_UP;
    htim7.Init.Period = COMM_DATA_PD_TIMER_PERIOD;
    htim7.Init.AutoReloadPreload = TIM_AUTORELOAD_PRELOAD_DISABLE;
    if (HAL_TIM_Base_Init(&htim7) != HAL_OK) {
        Error_Handler();
    }
    sMasterConfig.MasterOutputTrigger = TIM_TRGO_RESET;
    sMasterConfig.MasterSlaveMode = TIM_MASTERSLAVEMODE_DISABLE;
    if (HAL_TIMEx_MasterConfigSynchronization(&htim7, &sMasterConfig) != HAL_OK) {
        Error_Handler();
    }
}

static void MX_TIM8_Init(void)
{

    TIM_ClockConfigTypeDef sClockSourceConfig = {0};
    TIM_MasterConfigTypeDef sMasterConfig = {0};
    TIM_OC_InitTypeDef sConfigOC = {0};
    TIM_BreakDeadTimeConfigTypeDef sBreakDeadTimeConfig = {0};

    htim8.Instance = TIM8;
    htim8.Init.Prescaler = FAN_PSC;
    htim8.Init.CounterMode = TIM_COUNTERMODE_UP;
    htim8.Init.Period = FAN_ARR;
    htim8.Init.ClockDivision = TIM_CLOCKDIVISION_DIV1;
    htim8.Init.RepetitionCounter = 0;
    htim8.Init.AutoReloadPreload = TIM_AUTORELOAD_PRELOAD_DISABLE;
    if (HAL_TIM_Base_Init(&htim8) != HAL_OK) {
        Error_Handler();
    }
    sClockSourceConfig.ClockSource = TIM_CLOCKSOURCE_INTERNAL;
    if (HAL_TIM_ConfigClockSource(&htim8, &sClockSourceConfig) != HAL_OK) {
        Error_Handler();
    }
    if (HAL_TIM_PWM_Init(&htim8) != HAL_OK) {
        Error_Handler();
    }
    sMasterConfig.MasterOutputTrigger = TIM_TRGO_RESET;
    sMasterConfig.MasterSlaveMode = TIM_MASTERSLAVEMODE_DISABLE;
    if (HAL_TIMEx_MasterConfigSynchronization(&htim8, &sMasterConfig) != HAL_OK) {
        Error_Handler();
    }
    sConfigOC.OCMode = TIM_OCMODE_PWM1;
    sConfigOC.Pulse = FAN_CCR;
    sConfigOC.OCPolarity = TIM_OCPOLARITY_HIGH;
    sConfigOC.OCNPolarity = TIM_OCNPOLARITY_HIGH;
    sConfigOC.OCFastMode = TIM_OCFAST_DISABLE;
    sConfigOC.OCIdleState = TIM_OCIDLESTATE_RESET;
    sConfigOC.OCNIdleState = TIM_OCNIDLESTATE_RESET;
    if (HAL_TIM_PWM_ConfigChannel(&htim8, &sConfigOC, TIM_CHANNEL_1) != HAL_OK) {
        Error_Handler();
    }
    sBreakDeadTimeConfig.OffStateRunMode = TIM_OSSR_DISABLE;
    sBreakDeadTimeConfig.OffStateIDLEMode = TIM_OSSI_DISABLE;
    sBreakDeadTimeConfig.LockLevel = TIM_LOCKLEVEL_OFF;
    sBreakDeadTimeConfig.DeadTime = 0;
    sBreakDeadTimeConfig.BreakState = TIM_BREAK_DISABLE;
    sBreakDeadTimeConfig.BreakPolarity = TIM_BREAKPOLARITY_HIGH;
    sBreakDeadTimeConfig.AutomaticOutput = TIM_AUTOMATICOUTPUT_DISABLE;
    if (HAL_TIMEx_ConfigBreakDeadTime(&htim8, &sBreakDeadTimeConfig) != HAL_OK) {
        Error_Handler();
    }
    HAL_TIM_MspPostInit(&htim8);
}

static void MX_TIM9_Init(void)
{

    TIM_ClockConfigTypeDef sClockSourceConfig = {0};
    TIM_OC_InitTypeDef sConfigOC = {0};

    htim9.Instance = TIM9;
    htim9.Init.Prescaler = BEEP_TIM_PSC;
    htim9.Init.CounterMode = TIM_COUNTERMODE_UP;
    htim9.Init.Period = 36;
    htim9.Init.ClockDivision = TIM_CLOCKDIVISION_DIV1;
    htim9.Init.AutoReloadPreload = TIM_AUTORELOAD_PRELOAD_DISABLE;
    if (HAL_TIM_Base_Init(&htim9) != HAL_OK) {
        Error_Handler();
    }
    sClockSourceConfig.ClockSource = TIM_CLOCKSOURCE_INTERNAL;
    if (HAL_TIM_ConfigClockSource(&htim9, &sClockSourceConfig) != HAL_OK) {
        Error_Handler();
    }
    if (HAL_TIM_PWM_Init(&htim9) != HAL_OK) {
        Error_Handler();
    }
    sConfigOC.OCMode = TIM_OCMODE_PWM1;
    sConfigOC.Pulse = 18;
    sConfigOC.OCPolarity = TIM_OCPOLARITY_HIGH;
    sConfigOC.OCFastMode = TIM_OCFAST_DISABLE;
    if (HAL_TIM_PWM_ConfigChannel(&htim9, &sConfigOC, TIM_CHANNEL_2) != HAL_OK) {
        Error_Handler();
    }
    HAL_TIM_MspPostInit(&htim9);
}

static void MX_TIM10_Init(void)
{

    TIM_IC_InitTypeDef sConfigIC = {0};

    htim10.Instance = TIM10;
    htim10.Init.Prescaler = FAN_IC_PSC;
    htim10.Init.CounterMode = TIM_COUNTERMODE_UP;
    htim10.Init.Period = FAN_IC_ARR;
    htim10.Init.ClockDivision = TIM_CLOCKDIVISION_DIV1;
    htim10.Init.AutoReloadPreload = TIM_AUTORELOAD_PRELOAD_DISABLE;
    if (HAL_TIM_Base_Init(&htim10) != HAL_OK) {
        Error_Handler();
    }
    if (HAL_TIM_IC_Init(&htim10) != HAL_OK) {
        Error_Handler();
    }
    sConfigIC.ICPolarity = TIM_INPUTCHANNELPOLARITY_RISING;
    sConfigIC.ICSelection = TIM_ICSELECTION_DIRECTTI;
    sConfigIC.ICPrescaler = TIM_ICPSC_DIV1;
    sConfigIC.ICFilter = FAN_IC_IF;
    if (HAL_TIM_IC_ConfigChannel(&htim10, &sConfigIC, TIM_CHANNEL_1) != HAL_OK) {
        Error_Handler();
    }
}

static void MX_UART5_Init(void)
{

    huart5.Instance = UART5;
    huart5.Init.BaudRate = 115200;
    huart5.Init.WordLength = UART_WORDLENGTH_8B;
    huart5.Init.StopBits = UART_STOPBITS_1;
    huart5.Init.Parity = UART_PARITY_NONE;
    huart5.Init.Mode = UART_MODE_TX_RX;
    huart5.Init.HwFlowCtl = UART_HWCONTROL_NONE;
    huart5.Init.OverSampling = UART_OVERSAMPLING_16;
    if (HAL_UART_Init(&huart5) != HAL_OK) {
        Error_Handler();
    }
}

static void MX_USART1_UART_Init(void)
{

    huart1.Instance = USART1;
    huart1.Init.BaudRate = 115200;
    huart1.Init.WordLength = UART_WORDLENGTH_8B;
    huart1.Init.StopBits = UART_STOPBITS_1;
    huart1.Init.Parity = UART_PARITY_NONE;
    huart1.Init.Mode = UART_MODE_TX_RX;
    huart1.Init.HwFlowCtl = UART_HWCONTROL_NONE;
    huart1.Init.OverSampling = UART_OVERSAMPLING_16;
    if (HAL_UART_Init(&huart1) != HAL_OK) {
        Error_Handler();
    }
}

static void MX_USART2_UART_Init(void)
{

    huart2.Instance = USART2;
    huart2.Init.BaudRate = 115200;
    huart2.Init.WordLength = UART_WORDLENGTH_8B;
    huart2.Init.StopBits = UART_STOPBITS_1;
    huart2.Init.Parity = UART_PARITY_NONE;
    huart2.Init.Mode = UART_MODE_TX_RX;
    huart2.Init.HwFlowCtl = UART_HWCONTROL_NONE;
    huart2.Init.OverSampling = UART_OVERSAMPLING_16;
    if (HAL_UART_Init(&huart2) != HAL_OK) {
        Error_Handler();
    }
}

static void MX_USART3_UART_Init(void)
{

    huart3.Instance = USART3;
    huart3.Init.BaudRate = 9600;
    huart3.Init.WordLength = UART_WORDLENGTH_8B;
    huart3.Init.StopBits = UART_STOPBITS_1;
    huart3.Init.Parity = UART_PARITY_NONE;
    huart3.Init.Mode = UART_MODE_TX_RX;
    huart3.Init.HwFlowCtl = UART_HWCONTROL_NONE;
    huart3.Init.OverSampling = UART_OVERSAMPLING_16;
    if (HAL_UART_Init(&huart3) != HAL_OK) {
        Error_Handler();
    }
}

static void MX_DMA_Init(void)
{

    /* DMA controller clock enable */
    __HAL_RCC_DMA1_CLK_ENABLE();
    __HAL_RCC_DMA2_CLK_ENABLE();

    /* DMA interrupt init */
    /* DMA1_Stream0_IRQn interrupt configuration */
    HAL_NVIC_SetPriority(DMA1_Stream0_IRQn, 5, 0);
    HAL_NVIC_EnableIRQ(DMA1_Stream0_IRQn);
    /* DMA1_Stream5_IRQn interrupt configuration */
    HAL_NVIC_SetPriority(DMA1_Stream5_IRQn, 5, 0);
    HAL_NVIC_EnableIRQ(DMA1_Stream5_IRQn);
    /* DMA1_Stream6_IRQn interrupt configuration */
    HAL_NVIC_SetPriority(DMA1_Stream6_IRQn, 5, 0);
    HAL_NVIC_EnableIRQ(DMA1_Stream6_IRQn);
    /* DMA1_Stream7_IRQn interrupt configuration */
    HAL_NVIC_SetPriority(DMA1_Stream7_IRQn, 5, 0);
    HAL_NVIC_EnableIRQ(DMA1_Stream7_IRQn);
    /* DMA2_Stream0_IRQn interrupt configuration */
    HAL_NVIC_SetPriority(DMA2_Stream0_IRQn, 5, 0);
    HAL_NVIC_EnableIRQ(DMA2_Stream0_IRQn);
    /* DMA2_Stream2_IRQn interrupt configuration */
    HAL_NVIC_SetPriority(DMA2_Stream2_IRQn, 5, 0);
    HAL_NVIC_EnableIRQ(DMA2_Stream2_IRQn);
    /* DMA2_Stream5_IRQn interrupt configuration */
    HAL_NVIC_SetPriority(DMA2_Stream5_IRQn, 6, 0);
    HAL_NVIC_EnableIRQ(DMA2_Stream5_IRQn);
    /* DMA2_Stream7_IRQn interrupt configuration */
    HAL_NVIC_SetPriority(DMA2_Stream7_IRQn, 5, 0);
    HAL_NVIC_EnableIRQ(DMA2_Stream7_IRQn);
}

static void MX_GPIO_Init(void)
{
    GPIO_InitTypeDef GPIO_InitStruct = {0};

    /* GPIO Ports Clock Enable */
    __HAL_RCC_GPIOE_CLK_ENABLE();
    __HAL_RCC_GPIOC_CLK_ENABLE();
    __HAL_RCC_GPIOH_CLK_ENABLE();
    __HAL_RCC_GPIOA_CLK_ENABLE();
    __HAL_RCC_GPIOB_CLK_ENABLE();
    __HAL_RCC_GPIOD_CLK_ENABLE();

    /*Configure GPIO pin Output Level */
    HAL_GPIO_WritePin(GPIOC, STEP_NCS1_Pin | FAN_EN_Pin | LED_RUN_Pin, GPIO_PIN_RESET);

    /*Configure GPIO pin Output Level */
    HAL_GPIO_WritePin(BC_AIM_WK_N_GPIO_Port, BC_AIM_WK_N_Pin, GPIO_PIN_SET);

    /*Configure GPIO pin Output Level */
    HAL_GPIO_WritePin(GPIOE, STEP_NRST_Pin | BC_TRIG_N_Pin, GPIO_PIN_SET);

    /*Configure GPIO pin Output Level */
    HAL_GPIO_WritePin(GPIOE, STEP_NCS2_Pin | STEP_DIR2_Pin, GPIO_PIN_RESET);

    /*Configure GPIO pin Output Level */
    HAL_GPIO_WritePin(MOT_NRST_GPIO_Port, MOT_NRST_Pin, GPIO_PIN_SET);

    /*Configure GPIO pin Output Level */
    HAL_GPIO_WritePin(GPIOD, MOT_NCS1_Pin | MOT_NCS2_Pin | FRONT_STATUS_Pin, GPIO_PIN_SET);

    /*Configure GPIO pin Output Level */
    HAL_GPIO_WritePin(GPIOA, LAMP1_Pin | LAMP2_Pin | LAMP3_Pin, GPIO_PIN_RESET);

    /*Configure GPIO pin Output Level */
    HAL_GPIO_WritePin(SPI1_NSS_GPIO_Port, SPI1_NSS_Pin, GPIO_PIN_SET);

    /*Configure GPIO pin Output Level */
    HAL_GPIO_WritePin(STEP_DIR1_GPIO_Port, STEP_DIR1_Pin, GPIO_PIN_RESET);

    /*Configure GPIO pin : OPTSW_OUT2_Pin */
    GPIO_InitStruct.Pin = OPTSW_OUT2_Pin;
    GPIO_InitStruct.Mode = GPIO_MODE_IT_RISING_FALLING;
    GPIO_InitStruct.Pull = GPIO_NOPULL;
    HAL_GPIO_Init(OPTSW_OUT2_GPIO_Port, &GPIO_InitStruct);

    /*Configure GPIO pins : OPTSW_OUT3_Pin OPTSW_OUT4_Pin OPTSW_OUT0_Pin OPTSW_OUT1_Pin */
    GPIO_InitStruct.Pin = OPTSW_OUT3_Pin | OPTSW_OUT4_Pin | OPTSW_OUT0_Pin | OPTSW_OUT1_Pin;
    GPIO_InitStruct.Mode = GPIO_MODE_INPUT;
    GPIO_InitStruct.Pull = GPIO_PULLUP;
    HAL_GPIO_Init(GPIOE, &GPIO_InitStruct);

    /*Configure GPIO pins : PE5 PE7 PE8 PE11
                             STEP_NFLG2_Pin */
    GPIO_InitStruct.Pin = GPIO_PIN_5 | GPIO_PIN_7 | GPIO_PIN_8 | GPIO_PIN_11 | STEP_NFLG2_Pin;
    GPIO_InitStruct.Mode = GPIO_MODE_INPUT;
    GPIO_InitStruct.Pull = GPIO_NOPULL;
    HAL_GPIO_Init(GPIOE, &GPIO_InitStruct);

    /*Configure GPIO pins : STEP_NCS1_Pin BC_AIM_WK_N_Pin FAN_EN_Pin LED_RUN_Pin */
    GPIO_InitStruct.Pin = STEP_NCS1_Pin | BC_AIM_WK_N_Pin | FAN_EN_Pin | LED_RUN_Pin;
    GPIO_InitStruct.Mode = GPIO_MODE_OUTPUT_PP;
    GPIO_InitStruct.Pull = GPIO_NOPULL;
    GPIO_InitStruct.Speed = GPIO_SPEED_FREQ_LOW;
    HAL_GPIO_Init(GPIOC, &GPIO_InitStruct);

    /*Configure GPIO pins : STEP_NFLG1_Pin PC15 PC4 PC9
                             PC11 */
    GPIO_InitStruct.Pin = STEP_NFLG1_Pin | GPIO_PIN_15 | GPIO_PIN_4 | GPIO_PIN_9 | GPIO_PIN_11;
    GPIO_InitStruct.Mode = GPIO_MODE_INPUT;
    GPIO_InitStruct.Pull = GPIO_NOPULL;
    HAL_GPIO_Init(GPIOC, &GPIO_InitStruct);

    /*Configure GPIO pins : PB1 PB2 PB3 PB4
                             CARD_IN_Pin */
    GPIO_InitStruct.Pin = GPIO_PIN_1 | GPIO_PIN_2 | GPIO_PIN_3 | GPIO_PIN_4 | CARD_IN_Pin;
    GPIO_InitStruct.Mode = GPIO_MODE_INPUT;
    GPIO_InitStruct.Pull = GPIO_NOPULL;
    HAL_GPIO_Init(GPIOB, &GPIO_InitStruct);

    /*Configure GPIO pins : STEP_NRST_Pin STEP_NCS2_Pin STEP_DIR2_Pin BC_TRIG_N_Pin */
    GPIO_InitStruct.Pin = STEP_NRST_Pin | STEP_NCS2_Pin | STEP_DIR2_Pin | BC_TRIG_N_Pin;
    GPIO_InitStruct.Mode = GPIO_MODE_OUTPUT_PP;
    GPIO_InitStruct.Pull = GPIO_NOPULL;
    GPIO_InitStruct.Speed = GPIO_SPEED_FREQ_LOW;
    HAL_GPIO_Init(GPIOE, &GPIO_InitStruct);

    /*Configure GPIO pins : MOT_NRST_Pin STEP_DIR1_Pin */
    GPIO_InitStruct.Pin = MOT_NRST_Pin | STEP_DIR1_Pin;
    GPIO_InitStruct.Mode = GPIO_MODE_OUTPUT_PP;
    GPIO_InitStruct.Pull = GPIO_NOPULL;
    GPIO_InitStruct.Speed = GPIO_SPEED_FREQ_LOW;
    HAL_GPIO_Init(GPIOB, &GPIO_InitStruct);

    /*Configure GPIO pins : MOT_NCS1_Pin MOT_NCS2_Pin */
    GPIO_InitStruct.Pin = MOT_NCS1_Pin | MOT_NCS2_Pin;
    GPIO_InitStruct.Mode = GPIO_MODE_OUTPUT_PP;
    GPIO_InitStruct.Pull = GPIO_NOPULL;
    GPIO_InitStruct.Speed = GPIO_SPEED_FREQ_LOW;
    HAL_GPIO_Init(GPIOD, &GPIO_InitStruct);

    /*Configure GPIO pins : MOT_NBUSY1_Pin MOT_NFLG2_Pin MOT_NFLG1_Pin MOT_NBUSY2_Pin
                             PD14 OPTSW_OUT5_Pin OPTSW_OUT6_Pin FRONT_RESET_Pin */
    GPIO_InitStruct.Pin = MOT_NBUSY1_Pin | MOT_NFLG2_Pin | MOT_NFLG1_Pin | MOT_NBUSY2_Pin | GPIO_PIN_14 | OPTSW_OUT5_Pin | OPTSW_OUT6_Pin | FRONT_RESET_Pin;
    GPIO_InitStruct.Mode = GPIO_MODE_INPUT;
    GPIO_InitStruct.Pull = GPIO_NOPULL;
    HAL_GPIO_Init(GPIOD, &GPIO_InitStruct);

    /*Configure GPIO pins : LAMP1_Pin LAMP2_Pin LAMP3_Pin SPI1_NSS_Pin */
    GPIO_InitStruct.Pin = LAMP1_Pin | LAMP2_Pin | LAMP3_Pin | SPI1_NSS_Pin;
    GPIO_InitStruct.Mode = GPIO_MODE_OUTPUT_PP;
    GPIO_InitStruct.Pull = GPIO_NOPULL;
    GPIO_InitStruct.Speed = GPIO_SPEED_FREQ_LOW;
    HAL_GPIO_Init(GPIOA, &GPIO_InitStruct);

    /*Configure GPIO pin : FRONT_TRIG_IN_Pin */
    GPIO_InitStruct.Pin = FRONT_TRIG_IN_Pin;
    GPIO_InitStruct.Mode = GPIO_MODE_IT_RISING_FALLING;
    GPIO_InitStruct.Pull = GPIO_NOPULL;
    HAL_GPIO_Init(FRONT_TRIG_IN_GPIO_Port, &GPIO_InitStruct);

    /*Configure GPIO pin : FRONT_STATUS_Pin */
    GPIO_InitStruct.Pin = FRONT_STATUS_Pin;
    GPIO_InitStruct.Mode = GPIO_MODE_OUTPUT_PP;
    GPIO_InitStruct.Pull = GPIO_NOPULL;
    GPIO_InitStruct.Speed = GPIO_SPEED_FREQ_VERY_HIGH;
    HAL_GPIO_Init(FRONT_STATUS_GPIO_Port, &GPIO_InitStruct);

    /* EXTI interrupt init*/
    HAL_NVIC_SetPriority(EXTI2_IRQn, 5, 0);
    HAL_NVIC_EnableIRQ(EXTI2_IRQn);

    HAL_NVIC_SetPriority(EXTI4_IRQn, 5, 0);
    HAL_NVIC_EnableIRQ(EXTI4_IRQn);
}

/* USER CODE BEGIN 4 */
/**
 * @brief  错需信息打印
 * @param  file 文件名
 * @param  line 行数
 * @retval None
 */
void FL_Error_Handler(char * file, int line)
{
    const char plan_1[] = "error handle invoked in FILE: ";
    const char plan_2[] = " | LINE: ";
    uint8_t line_buffer[5], i;

    HAL_UART_Transmit(&huart5, (uint8_t *)plan_1, strlen(plan_1), 30);
    HAL_UART_Transmit(&huart5, (uint8_t *)file, strlen(file), 30);

    HAL_UART_Transmit(&huart5, (uint8_t *)plan_2, strlen(plan_2), 30);

    for (i = 0; i < 4; ++i) {
        line_buffer[3 - i] = '0' + line % 10;
        line /= 10;
    }
    line_buffer[4] = '\n';

    HAL_UART_Transmit(&huart5, line_buffer, 5, 30);
}

/**
 * @brief  获取硬件版本 PB0 处电压
 * @param  None
 * @retval 硬件版本号 1.2->12
 * @note 1 mV = 3300 / 4095 = 0.8058608058608059
 * @note 硬件版本 v1.1/v1.0 电压为 0V
 * @note 硬件版本 v1.2 电压为1.65V
 * @note ADC 故障返回 0xFE 值不再范围内 返回0xFF
 */
uint8_t GetHardwareVersion(void)
{
    uint32_t voltage;
    uint8_t version;

    HAL_ADC_Start(&hadc2);
    if (HAL_ADC_PollForConversion(&hadc2, 100) == HAL_OK) {
        voltage = HAL_ADC_GetValue(&hadc2);
    } else {
        HAL_ADC_Stop(&hadc2); /* 停止ADC采样 */
        return 0xFE;          /* ADC 转换故障 */
    }

    if (voltage <= 410) {                            /* 0~0.33 */
        version = 11;                                /* v1.1 */
    } else if (voltage <= 2457 && voltage >= 1638) { /* 1.65 ± 0.33 */
        version = 12;                                /* v1.2 */
    } else {                                         /* 值不再范围内 */
        version = 0xFF;                              /* ERROR */
    }
    HAL_ADC_Stop(&hadc2); /* 停止ADC采样 */
    return version;
}

/**
 * @brief  杂项任务 通知提交
 * @param  notify 通知值
 * @retval 通知结果
 */
BaseType_t Miscellaneous_Task_Notify(uint32_t notify)
{
    BaseType_t xResult;

    xResult = xTaskNotify(Miscellaneous_Task_Handle, notify, eSetValueWithoutOverwrite);
    return xResult;
}

/**
 * @brief  杂项任务 是否处于忙状态
 * @param  None
 * @retval 0 空闲 1 忙碌
 */
uint8_t Miscellaneous_Task_Is_Busy(void)
{
    return Miscellaneous_Task_State > 0;
}

/**
 * @brief  杂项任务
 * @param  argument: Not used
 * @retval None
 */
static void Miscellaneous_Task(void * argument)
{
    TickType_t xTick;
    uint32_t cnt = 0, notify, pre_light_start, pre_light_stop;
    BaseType_t xResult;
    uint8_t buffer[16];

    temp_Start_ADC_DMA();                         /* 启动ADC转换 */
    fan_Init();                                   /* 风扇初始化 */
    protocol_Temp_Upload_Comm_Set(eComm_Out, 0);  /* 关闭外串口发送 */
    protocol_Temp_Upload_Comm_Set(eComm_Main, 0); /* 关闭主板发送 */
    xTick = xTaskGetTickCount();                  /* 获取系统时刻 */
    vTaskDelay(30);                               /* ADC 转换完成 */
    pre_light_start = 0;
    pre_light_stop = 0;

    for (;;) {
        xResult = xTaskNotifyWait(0, 0xFFFFFFFF, &notify, 80);
        if (xResult) {
            switch (notify) {
                case 0:
                default:
                    Miscellaneous_Task_State = 1;
                    white_Motor_PD(); /* 运动白板电机 PD位置 */
                    white_Motor_WH(); /* 运动白板电机 白物质位置 */
                    Miscellaneous_Task_State = 0;
                    break;
                case 1:
                    pre_light_start = xTick;
                    break;
            }
        }

        if (pre_light_start && xTick - pre_light_start > 100) {
            pre_light_start = 0;
            comm_Data_Pre_Light_Start(buffer);
            pre_light_stop = xTick;
        }
        if (pre_light_stop && xTick - pre_light_stop > 5000) {
            pre_light_stop = 0;
            comm_Data_Pre_Light_Stop(buffer);
        }

        fan_Ctrl_Deal(temp_Get_Temp_Data_ENV()); /* 根据环境温度调整风扇输出 */
        fan_IC_Error_Deal();                     /* 风扇转速监控 */
        led_Out_Deal(xTick);                     /* 外接LED板处理 */
        protocol_Temp_Upload_Deal();             /* 温度信息上送处理 */

        if (cnt % 5 == 0) {           /* 500mS */
            led_Board_Green_Toggle(); /* 板上运行灯闪烁 */
        }

        vTaskDelayUntil(&xTick, 100);
        ++cnt;
    }
}

/* USER CODE END 4 */

void StartDefaultTask(void * argument)
{
    /* USER CODE BEGIN 5 */
    /* Infinite loop */
    uint32_t a = 0;

    /* Infinite loop */
    for (;;) {
        if (a % 100 == 0) {
            HAL_GPIO_TogglePin(LAMP1_GPIO_Port, LAMP1_Pin);
            HAL_GPIO_TogglePin(LAMP2_GPIO_Port, LAMP2_Pin);
            HAL_GPIO_TogglePin(LAMP3_GPIO_Port, LAMP3_Pin);
            HAL_GPIO_TogglePin(LED_RUN_GPIO_Port, LED_RUN_Pin);
        }
        ++a;
        vTaskDelay(1);
    }
    /* USER CODE END 5 */
}

void HAL_TIM_PeriodElapsedCallback(TIM_HandleTypeDef * htim)
{
    /* USER CODE BEGIN Callback 0 */
    if (htim->Instance == TIM1) {
        if (PWM_AW_IRQ_CallBcak() == 0) { /* 运动完成 */
            m_drv8824_release_ISR();      /* 释放PWM资源 */
        }
    }
    /* USER CODE END Callback 0 */
    if (htim->Instance == TIM14) {
        HAL_IncTick();
    }
}

void Error_Handler(void)
{
}

/************************ (C) COPYRIGHT STMicroelectronics *****END OF FILE****/
